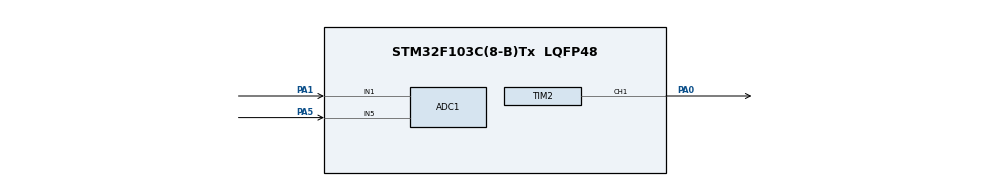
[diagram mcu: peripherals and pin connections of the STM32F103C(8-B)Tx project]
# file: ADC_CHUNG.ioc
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ADC1.Channel-0\#ChannelRegularConversion=ADC_CHANNEL_5
ADC1.Channel-1\#ChannelRegularConversion=ADC_CHANNEL_1
ADC1.NbrOfConversion=2
ADC1.NbrOfConversionFlag=1
ADC1.Rank-0\#ChannelRegularConversion=1
ADC1.Rank-1\#ChannelRegularConversion=2
ADC1.SamplingTime-0\#ChannelRegularConversion=ADC_SAMPLETIME_28CYCLES_5
ADC1.SamplingTime-1\#ChannelRegularConversion=ADC_SAMPLETIME_28CYCLES_5
ADC1.master=1
Mcu.Family=STM32F1
Mcu.Name=STM32F103C(8-B)Tx
Mcu.Package=LQFP48
NVIC.PriorityGroup=NVIC_PRIORITYGROUP_4
PA0-WKUP.Signal=S_TIM2_CH1_ETR
PA1.Signal=ADCx_IN1
PA5.Signal=ADCx_IN5
PD0-OSC_IN.Mode=HSE-External-Clock-Source
PD0-OSC_IN.Signal=RCC_OSC_IN
PD1-OSC_OUT.Mode=HSE-External-Clock-Source
PD1-OSC_OUT.Signal=RCC_OSC_OUT
ProjectManager.HeapSize=0x200
ProjectManager.StackSize=0x400
ProjectManager.TargetToolchain=MDK-ARM V5.32
RCC.APB1CLKDivider=RCC_HCLK_DIV2
RCC.APB1Freq_Value=4000000
RCC.APB1TimFreq_Value=8000000
RCC.APB2Freq_Value=8000000
SH.ADCx_IN1.0=ADC1_IN1,IN1
SH.ADCx_IN5.0=ADC1_IN5,IN5
SH.S_TIM2_CH1_ETR.0=TIM2_CH1,PWM Generation1 CH1
TIM2.AutoReloadPreload=TIM_AUTORELOAD_PRELOAD_ENABLE
TIM2.Channel-PWM\ Generation1\ CH1=TIM_CHANNEL_1
TIM2.Prescaler=71
VP_SYS_VS_ND.Mode=No_Debug
VP_TIM2_VS_ClockSourceINT.Mode=Internal
board=custom

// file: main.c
/* USER CODE BEGIN Header */
/**
  ******************************************************************************
  * @file           : main.c
  * @brief          : Main program body
  ******************************************************************************
  */
/* USER CODE END Header */
#include "main.h"

ADC_HandleTypeDef hadc1;
TIM_HandleTypeDef htim2;

/* USER CODE BEGIN PV */
uint16_t Vamb = 0;
uint32_t DC_Multiplier = 1;

uint16_t PWM_final = 0;
uint16_t PWM_from_light = 0;
uint16_t PWM_from_pot = 0;
/* USER CODE END PV */

void SystemClock_Config(void);
static void MX_GPIO_Init(void);
static void MX_ADC1_Init(void);
static void MX_TIM2_Init(void);

/* USER CODE BEGIN 0 */
// Hàm đọc trung bình nhiều mẫu từ 1 kênh ADC
uint16_t Read_ADC_Channel(uint32_t channel)
{
    ADC_ChannelConfTypeDef sConfig = {0};
    sConfig.Channel = channel;
    sConfig.Rank = ADC_REGULAR_RANK_1;
    sConfig.SamplingTime = ADC_SAMPLETIME_28CYCLES_5;
    HAL_ADC_ConfigChannel(&hadc1, &sConfig);

    uint32_t sum = 0;
    for (int i = 0; i < 16; i++) // Lấy trung bình 16 mẫu
    {
        HAL_ADC_Start(&hadc1);
        HAL_ADC_PollForConversion(&hadc1, HAL_MAX_DELAY);
        sum += HAL_ADC_GetValue(&hadc1);
    }
    return (uint16_t)(sum / 16);
}
/* USER CODE END 0 */

int main(void)
{
  HAL_Init();
  SystemClock_Config();

  MX_GPIO_Init();
  MX_ADC1_Init();
  MX_TIM2_Init();

  /* USER CODE BEGIN 2 */
  HAL_TIM_PWM_Start(&htim2, TIM_CHANNEL_1);

  // Hiệu chỉnh ADC
  HAL_ADCEx_Calibration_Start(&hadc1);

  // Đọc giá trị ánh sáng môi trường ban đầu
  Vamb = Read_ADC_Channel(ADC_CHANNEL_5);
  if (Vamb >= 4095) Vamb = 4094;  // tránh chia 0
  DC_Multiplier = htim2.Init.Period / (4096 - Vamb);
  /* USER CODE END 2 */

  /* Infinite loop */
  while (1)
  {
    // Đọc cảm biến ánh sáng (kênh 5)
    uint16_t lightValue = Read_ADC_Channel(ADC_CHANNEL_5);

    // Đọc biến trở (kênh 1)
    uint16_t potValue = Read_ADC_Channel(ADC_CHANNEL_1);

    // PWM từ ánh sáng
    if (lightValue > Vamb)
        PWM_from_light = (uint16_t)((lightValue - Vamb) * DC_Multiplier);
    else
        PWM_from_light = 0;

    if (PWM_from_light > htim2.Init.Period)
        PWM_from_light = htim2.Init.Period;

    // PWM từ biến trở (scale 0-4095 -> 0-ARR)
    PWM_from_pot = (uint16_t)((potValue * htim2.Init.Period) / 4095);

    // PWM chung = kết hợp (tỷ lệ với biến trở)
    PWM_final = (uint16_t)(((uint32_t)PWM_from_light * PWM_from_pot) / htim2.Init.Period);

    // Xuất PWM chung ra TIM2_CH1
    __HAL_TIM_SET_COMPARE(&htim2, TIM_CHANNEL_1, PWM_final);

    HAL_Delay(10);
  }
}
